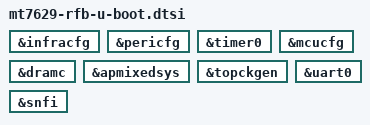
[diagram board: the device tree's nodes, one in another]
// SPDX-License-Identifier: GPL-2.0
/*
 * Copyright (C) 2018 MediaTek Inc.
 *
 * Author: Weijie Gao <weijie.gao@mediatek.com>
 */

&infracfg {
	u-boot,dm-all;
};

&pericfg {
	u-boot,dm-all;
};

&timer0 {
	u-boot,dm-all;
};

&mcucfg {
	u-boot,dm-all;
};

&dramc {
	u-boot,dm-all;
};

&apmixedsys {
	u-boot,dm-all;
};

&topckgen {
	u-boot,dm-all;
};

&uart0 {
	u-boot,dm-all;
};

&snfi {
	u-boot,dm-all;
};
